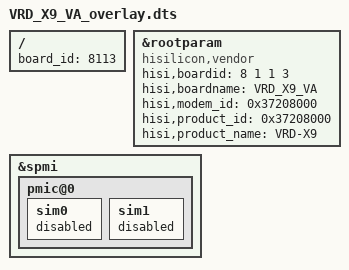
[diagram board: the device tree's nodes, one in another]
/**
 * Copyright (C) 2014 Hisilicon Ltd.
 *
 *  This program is free software; you can redistribute it and/or modify
 *  it under the terms of the GNU General Public License version 2 as
 *  publishhed by the Free Software Foundation.
 */

/dts-v1/;
/plugin/;
/include/ "VRD_AL09_VA_overlay.dtsi"
/include/ "VRD_X9_VA_pin.dtsi"
/include/ "VRD_X9_VA_modem_pin.dtsi"

/ {
    board_id = <8113>;
};

	&rootparam {
		compatible = "hisilicon,vendor";
		hisi,boardid = <8 1 1 3>;
		hisi,boardname = "VRD_X9_VA";
		hisi,modem_id = <0x37208000>;
		hisi,product_id = <0x37208000>;
		hisi,product_name = "VRD-X9";
	};

&spmi {
    pmic@0 {
        sim0 {
            status = "disabled";
        };

        sim1 {
            status = "disabled";
        };
    };
};
